AUTOSAR XML (schema 4-2-2)
package /Components
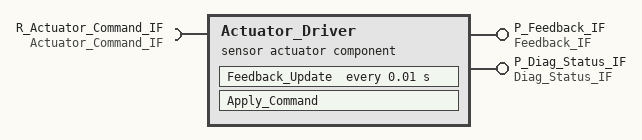
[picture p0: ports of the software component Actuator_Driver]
  sensor actuator sw component type Actuator_Driver
    provide port P_Feedback_IF: provided-interface=Feedback_IF
    provide port P_Diag_Status_IF: provided-interface=Diag_Status_IF
    require port R_Actuator_Command_IF: required-interface=Actuator_Command_IF
    behavior Actuator_Driver_IB
      data received event Actuator_Command_Updated: start-on-event=Apply_Command
      init event Actuator_Driver_Init: start-on-event=Apply_Command
      timing event Actuator_Driver_Cycle: start-on-event=Feedback_Update, period=0.01
      runnable Apply_Command: minimum-start-interval=0.01
        data-receive-point-by-arguments:
          access VA_RX_m1_pwm_duty: accessed-variable=R_Actuator_Command_IF.m1_pwm_duty
          access VA_RX_m2_pwm_duty: accessed-variable=R_Actuator_Command_IF.m2_pwm_duty
      runnable Feedback_Update: minimum-start-interval=0.01
        data-send-points:
          6 x access:
            VA_TX_m1_speed_meas: accessed-variable=P_Feedback_IF.m1_speed_meas
            VA_TX_m1_pos_meas: accessed-variable=P_Feedback_IF.m1_pos_meas
            VA_TX_m2_speed_meas: accessed-variable=P_Feedback_IF.m2_speed_meas
            VA_TX_m2_pos_meas: accessed-variable=P_Feedback_IF.m2_pos_meas
            VA_TX_diag_status: accessed-variable=P_Diag_Status_IF.diag_status
            VA_TX_fault_code: accessed-variable=P_Diag_Status_IF.fault_code
